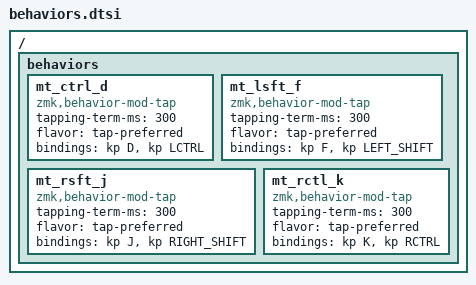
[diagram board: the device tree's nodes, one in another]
/ {
    behaviors {
        mt_ctrl_d: mt_ctrl_d {
            compatible = "zmk,behavior-mod-tap";
            #binding-cells = <0>;
            tapping-term-ms = <300>;
            flavor = "tap-preferred";
            bindings = <&kp D &kp LCTRL>;
        };

        mt_lsft_f: mt_lsft_f {
            compatible = "zmk,behavior-mod-tap";
            #binding-cells = <0>;
            tapping-term-ms = <300>;
            flavor = "tap-preferred";
            bindings = <&kp F &kp LEFT_SHIFT>;
        };

        mt_rsft_j: mt_rsft_j {
            compatible = "zmk,behavior-mod-tap";
            #binding-cells = <0>;
            tapping-term-ms = <300>;
            flavor = "tap-preferred";
            bindings = <&kp J &kp RIGHT_SHIFT>;
        };

        mt_rctl_k: mt_rctl_k {
            compatible = "zmk,behavior-mod-tap";
            #binding-cells = <0>;
            tapping-term-ms = <300>;
            flavor = "tap-preferred";
            bindings = <&kp K &kp RCTRL>;
        };
    };
};
